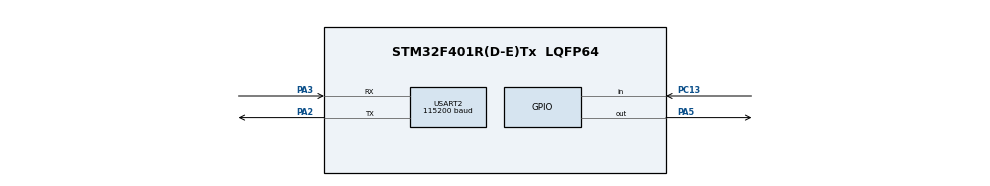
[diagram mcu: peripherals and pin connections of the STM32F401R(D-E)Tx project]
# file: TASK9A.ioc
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Mcu.Family=STM32F4
Mcu.Name=STM32F401R(D-E)Tx
Mcu.Package=LQFP64
NVIC.USART2_IRQn=true:0:0:false:false:true:true:true:true
PA2.Mode=Asynchronous
PA2.Signal=USART2_TX
PA3.Mode=Asynchronous
PA3.Signal=USART2_RX
PA5.Signal=GPIO_Output
PA13.Mode=Serial_Wire
PA13.Signal=SYS_JTMS-SWDIO
PA14.Mode=Serial_Wire
PA14.Signal=SYS_JTCK-SWCLK
PC13.Signal=GPIO_Input
PC13.GPIO_PuPd=GPIO_PULLUP
ProjectManager.TargetToolchain=MDK-ARM V5.32
RCC.AHBFreq_Value=84000000
RCC.APB1Freq_Value=42000000
RCC.APB2Freq_Value=84000000
RCC.CortexFreq_Value=84000000
RCC.HCLKFreq_Value=84000000
RCC.SYSCLKFreq_VALUE=84000000
RCC.SYSCLKSource=RCC_SYSCLKSOURCE_PLLCLK
USART2.BaudRate=115200
USART2.Parity=PARITY_NONE
USART2.StopBits=STOPBITS_1
USART2.WordLength=WORDLENGTH_8B
board=custom

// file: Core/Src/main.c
/* USER CODE BEGIN Header */
/**
  ******************************************************************************
  * @file           : main.c
  * @brief          : CAT 9 - TASK 9A: USART2 Terminal Character Echo Engine
  * Target Device   : STM32F401RET6 (NUCLEO-F401RE, ARM Cortex-M4 @ 84 MHz)
  * Pin Map         : PA2  -> USART2 TX (ST-LINK Virtual COM Port @ 115200)
  *                   PA3  -> USART2 RX (ST-LINK Virtual COM Port @ 115200)
  *                   PA5  -> Onboard Green LED LD2
  ******************************************************************************
  */
/* USER CODE END Header */
#include "main.h"

/* USER CODE BEGIN Includes */
#include <string.h>
#include <stdbool.h>
/* USER CODE END Includes */

UART_HandleTypeDef huart2;

/* USER CODE BEGIN PV */
uint8_t rx_char = 0;
/* USER CODE END PV */

void SystemClock_Config(void);
static void MX_GPIO_Init(void);
static void MX_USART2_UART_Init(void);

int main(void)
{
  /* USER CODE BEGIN 1 */
  char *banner = "\r\n=== NUCLEO-F401RE USART2 Terminal Echo ===\r\nType any character to echo back:\r\n";
  /* USER CODE END 1 */

  /* MCU Configuration--------------------------------------------------------*/

  /* Reset of all peripherals, Initializes the Flash interface and the Systick. */
  HAL_Init();

  /* Configure the system clock */
  SystemClock_Config();

  /* Initialize all configured peripherals */
  MX_GPIO_Init();
  MX_USART2_UART_Init();
  /* USER CODE BEGIN 2 */
  HAL_UART_Transmit(&huart2, (uint8_t *)banner, strlen(banner), HAL_MAX_DELAY);
  /* USER CODE END 2 */

  /* Infinite loop */
  /* USER CODE BEGIN WHILE */
  while (1)
  {
    /* Receive character and immediately echo back */
    if (HAL_UART_Receive(&huart2, &rx_char, 1, 10) == HAL_OK)
    {
      HAL_UART_Transmit(&huart2, &rx_char, 1, 10);
      HAL_GPIO_TogglePin(GPIOA, GPIO_PIN_5);
    }
    /* USER CODE END WHILE */

  }
}

void SystemClock_Config(void)
{
  RCC_OscInitTypeDef RCC_OscInitStruct = {0};
  RCC_ClkInitTypeDef RCC_ClkInitStruct = {0};

  __HAL_RCC_PWR_CLK_ENABLE();
  __HAL_PWR_VOLTAGESCALING_CONFIG(PWR_REGULATOR_VOLTAGE_SCALE2);

  RCC_OscInitStruct.OscillatorType = RCC_OSCILLATORTYPE_HSI;
  RCC_OscInitStruct.HSIState = RCC_HSI_ON;
  RCC_OscInitStruct.HSICalibrationValue = RCC_HSICALIBRATION_DEFAULT;
  RCC_OscInitStruct.PLL.PLLState = RCC_PLL_ON;
  RCC_OscInitStruct.PLL.PLLSource = RCC_PLLSOURCE_HSI;
  RCC_OscInitStruct.PLL.PLLM = 16;
  RCC_OscInitStruct.PLL.PLLN = 336;
  RCC_OscInitStruct.PLL.PLLP = RCC_PLLP_DIV4;
  RCC_OscInitStruct.PLL.PLLQ = 7;
  if (HAL_RCC_OscConfig(&RCC_OscInitStruct) != HAL_OK)
  {
    Error_Handler();
  }

  RCC_ClkInitStruct.ClockType = RCC_CLOCKTYPE_HCLK|RCC_CLOCKTYPE_SYSCLK
                              |RCC_CLOCKTYPE_PCLK1|RCC_CLOCKTYPE_PCLK2;
  RCC_ClkInitStruct.SYSCLKSource = RCC_SYSCLKSOURCE_PLLCLK;
  RCC_ClkInitStruct.AHBCLKDivider = RCC_SYSCLK_DIV1;
  RCC_ClkInitStruct.APB1CLKDivider = RCC_HCLK_DIV2;
  RCC_ClkInitStruct.APB2CLKDivider = RCC_HCLK_DIV1;

  if (HAL_RCC_ClockConfig(&RCC_ClkInitStruct, FLASH_LATENCY_2) != HAL_OK)
  {
    Error_Handler();
  }
}

static void MX_USART2_UART_Init(void)
{
  huart2.Instance = USART2;
  huart2.Init.BaudRate = 115200;
  huart2.Init.WordLength = UART_WORDLENGTH_8B;
  huart2.Init.StopBits = UART_STOPBITS_1;
  huart2.Init.Parity = UART_PARITY_NONE;
  huart2.Init.Mode = UART_MODE_TX_RX;
  huart2.Init.HwFlowCtl = UART_HWCONTROL_NONE;
  huart2.Init.OverSampling = UART_OVERSAMPLING_16;
  if (HAL_UART_Init(&huart2) != HAL_OK)
  {
    Error_Handler();
  }
}

static void MX_GPIO_Init(void)
{
  GPIO_InitTypeDef GPIO_InitStruct = {0};

  /* GPIO Ports Clock Enable */
  __HAL_RCC_GPIOA_CLK_ENABLE();

  /* Configure GPIO pin Output Level */
  HAL_GPIO_WritePin(GPIOA, GPIO_PIN_5, GPIO_PIN_RESET);

  /* Configure GPIO pin : PA5 (LD2 Green LED) */
  GPIO_InitStruct.Pin = GPIO_PIN_5;
  GPIO_InitStruct.Mode = GPIO_MODE_OUTPUT_PP;
  GPIO_InitStruct.Pull = GPIO_NOPULL;
  GPIO_InitStruct.Speed = GPIO_SPEED_FREQ_LOW;
  HAL_GPIO_Init(GPIOA, &GPIO_InitStruct);
}

void Error_Handler(void)
{
  __disable_irq();
  while (1)
  {
  }
}
